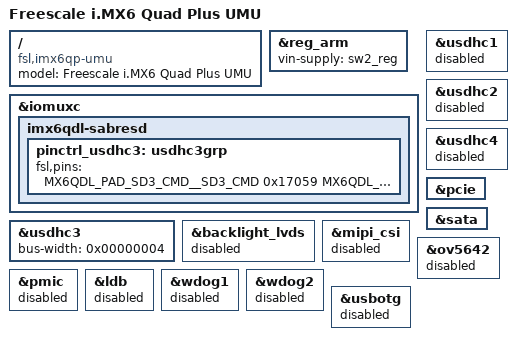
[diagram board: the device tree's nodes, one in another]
// SPDX-License-Identifier: GPL-2.0+ OR MIT
//
// Copyright 2022 Borsight, Inc.

/dts-v1/;

#include "imx6qp.dtsi"
#include "imx6qdl-sabresd.dtsi"

/ {
	model = "Freescale i.MX6 Quad Plus UMU";
	compatible = "fsl,imx6qp-umu", "fsl,imx6qp";
};

&reg_arm {
	vin-supply = <&sw2_reg>;
};

&iomuxc {
	imx6qdl-sabresd {
		pinctrl_usdhc3: usdhc3grp {
			fsl,pins = <
				MX6QDL_PAD_SD3_CMD__SD3_CMD		0x17059
				MX6QDL_PAD_SD3_CLK__SD3_CLK		0x10071
				MX6QDL_PAD_SD3_DAT0__SD3_DATA0		0x17059
				MX6QDL_PAD_SD3_DAT1__SD3_DATA1		0x17059
				MX6QDL_PAD_SD3_DAT2__SD3_DATA2		0x17059
				MX6QDL_PAD_SD3_DAT3__SD3_DATA3		0x17059
				MX6QDL_PAD_SD3_DAT4__SD3_DATA4		0x17059
				MX6QDL_PAD_SD3_DAT5__SD3_DATA5		0x17059
				MX6QDL_PAD_SD3_DAT6__SD3_DATA6		0x17059
				MX6QDL_PAD_SD3_DAT7__SD3_DATA7		0x17059
			>;
		};
	};
};

&usdhc1 {
	status = "disabled";
};

&usdhc2 {
	status = "disabled";
};

&usdhc3 {
	/delete-property/ cd-gpios;
	/delete-property/ wp-gpios;
	bus-width = <0x00000004>;
};

&usdhc4 {
	status = "disabled";
};


&pcie {
	status = "okay";
};

&sata {
	status = "okay";
};

&backlight_lvds {
	status = "disabled";
};

&mipi_csi {
	status = "disabled";
};

&ov5642 {
	status = "disabled";
};

&pmic {
	status = "disabled";
};

&ldb {
	status = "disabled";
};

&wdog1 {
	status = "disabled";
};

&wdog2 {
	status = "disabled";
};

&usbotg {
	status = "disabled";
};

///delete-node/ &leds;

///delete-node/ &panel;

///delete-node/ &gpio_leds;

///delete-node/ &gpio-keys;
